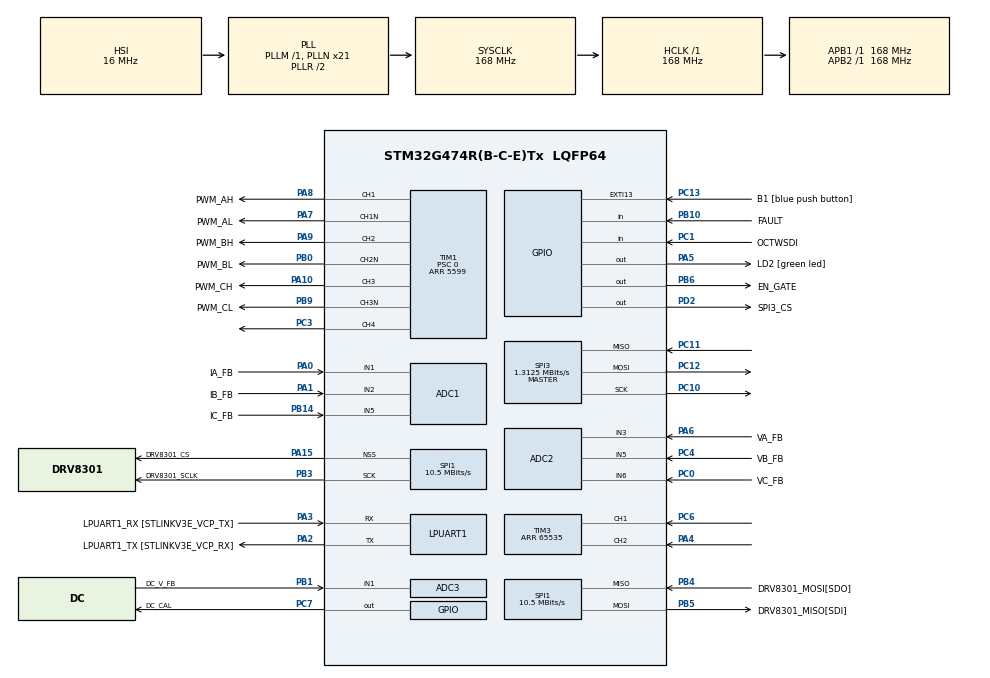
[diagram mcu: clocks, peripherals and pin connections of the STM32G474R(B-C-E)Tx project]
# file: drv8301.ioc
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ADC1.AWD1HighThreshold=4095
ADC1.AWD1ITMode=ENABLE
ADC1.Channel-0\#ChannelRegularConversion=ADC_CHANNEL_1
ADC1.Channel-2\#ChannelRegularConversion=ADC_CHANNEL_2
ADC1.Channel-3\#ChannelRegularConversion=ADC_CHANNEL_5
ADC1.ContinuousConvMode=DISABLE
ADC1.DMAAccessModeView=ENABLE
ADC1.DMAContinuousRequests=ENABLE
ADC1.EnableAnalogWatchDog1=true
ADC1.EnableInjectedConversion=ENABLE
ADC1.ExternalTrigInjecConv=ADC_EXTERNALTRIGINJEC_T1_TRGO2
ADC1.InjNumberOfConversion=3
ADC1.InjectedChannel-1\#ChannelInjectedConversion=ADC_CHANNEL_1
ADC1.InjectedChannel-4\#ChannelInjectedConversion=ADC_CHANNEL_2
ADC1.InjectedChannel-5\#ChannelInjectedConversion=ADC_CHANNEL_5
ADC1.InjectedConvMode=Discontinuous
ADC1.InjectedOffsetNumber-1\#ChannelInjectedConversion=ADC_OFFSET_NONE
ADC1.InjectedOffsetNumber-4\#ChannelInjectedConversion=ADC_OFFSET_NONE
ADC1.InjectedOffsetNumber-5\#ChannelInjectedConversion=ADC_OFFSET_NONE
ADC1.InjectedRank-1\#ChannelInjectedConversion=1
ADC1.InjectedRank-4\#ChannelInjectedConversion=2
ADC1.InjectedRank-5\#ChannelInjectedConversion=3
ADC1.InjectedSamplingTime-1\#ChannelInjectedConversion=ADC_SAMPLETIME_6CYCLES_5
ADC1.InjectedSamplingTime-4\#ChannelInjectedConversion=ADC_SAMPLETIME_6CYCLES_5
ADC1.InjectedSamplingTime-5\#ChannelInjectedConversion=ADC_SAMPLETIME_6CYCLES_5
ADC1.Mode=ADC_DUALMODE_REGSIMULT_INJECSIMULT
ADC1.NbrOfConversion=3
ADC1.NbrOfConversionFlag=1
ADC1.OffsetNumber-0\#ChannelRegularConversion=ADC_OFFSET_NONE
ADC1.OffsetNumber-2\#ChannelRegularConversion=ADC_OFFSET_NONE
ADC1.OffsetNumber-3\#ChannelRegularConversion=ADC_OFFSET_NONE
ADC1.Rank-0\#ChannelRegularConversion=1
ADC1.Rank-2\#ChannelRegularConversion=2
ADC1.Rank-3\#ChannelRegularConversion=3
ADC1.Rank2_Channel=ADC_CHANNEL_2
ADC1.Rank3_Channel=ADC_CHANNEL_5
ADC1.SamplingTime-0\#ChannelRegularConversion=ADC_SAMPLETIME_6CYCLES_5
ADC1.SamplingTime-2\#ChannelRegularConversion=ADC_SAMPLETIME_6CYCLES_5
ADC1.SamplingTime-3\#ChannelRegularConversion=ADC_SAMPLETIME_6CYCLES_5
ADC1.WatchdogMode=ADC_ANALOGWATCHDOG_ALL_REGINJEC
ADC1.injectedQueueMode=DISABLE
ADC1.master=1
ADC2.AWD1HighThreshold=4095
ADC2.AWD1ITMode=ENABLE
ADC2.Channel-1\#ChannelRegularConversion=ADC_CHANNEL_3
ADC2.Channel-2\#ChannelRegularConversion=ADC_CHANNEL_5
ADC2.Channel-3\#ChannelRegularConversion=ADC_CHANNEL_6
ADC2.DMAAccessModeView=ENABLE
ADC2.DMAContinuousRequests=ENABLE
ADC2.EnableAnalogWatchDog1=true
ADC2.EnableInjectedConversion=ENABLE
ADC2.InjNumberOfConversion=3
ADC2.InjectedChannel-4\#ChannelInjectedConversion=ADC_CHANNEL_3
ADC2.InjectedChannel-5\#ChannelInjectedConversion=ADC_CHANNEL_5
ADC2.InjectedChannel-6\#ChannelInjectedConversion=ADC_CHANNEL_6
ADC2.InjectedConvMode=Discontinuous
ADC2.InjectedOffsetNumber-4\#ChannelInjectedConversion=ADC_OFFSET_NONE
ADC2.InjectedOffsetNumber-5\#ChannelInjectedConversion=ADC_OFFSET_NONE
ADC2.InjectedOffsetNumber-6\#ChannelInjectedConversion=ADC_OFFSET_NONE
ADC2.InjectedRank-4\#ChannelInjectedConversion=1
ADC2.InjectedRank-5\#ChannelInjectedConversion=2
ADC2.InjectedRank-6\#ChannelInjectedConversion=3
ADC2.InjectedSamplingTime-4\#ChannelInjectedConversion=ADC_SAMPLETIME_6CYCLES_5
ADC2.InjectedSamplingTime-5\#ChannelInjectedConversion=ADC_SAMPLETIME_6CYCLES_5
ADC2.InjectedSamplingTime-6\#ChannelInjectedConversion=ADC_SAMPLETIME_6CYCLES_5
ADC2.Mode=ADC_DUALMODE_REGSIMULT_INJECSIMULT
ADC2.NbrOfConversion=3
ADC2.NbrOfConversionFlag=1
ADC2.OffsetNumber-1\#ChannelRegularConversion=ADC_OFFSET_NONE
ADC2.OffsetNumber-2\#ChannelRegularConversion=ADC_OFFSET_NONE
ADC2.OffsetNumber-3\#ChannelRegularConversion=ADC_OFFSET_NONE
ADC2.Rank-1\#ChannelRegularConversion=1
ADC2.Rank-2\#ChannelRegularConversion=2
ADC2.Rank-3\#ChannelRegularConversion=3
ADC2.Rank1_Channel=ADC_CHANNEL_3
ADC2.Rank2_Channel=ADC_CHANNEL_5
ADC2.Rank3_Channel=ADC_CHANNEL_6
ADC2.SamplingTime-1\#ChannelRegularConversion=ADC_SAMPLETIME_6CYCLES_5
ADC2.SamplingTime-2\#ChannelRegularConversion=ADC_SAMPLETIME_6CYCLES_5
ADC2.SamplingTime-3\#ChannelRegularConversion=ADC_SAMPLETIME_6CYCLES_5
ADC2.WatchdogMode=ADC_ANALOGWATCHDOG_ALL_REGINJEC
ADC2.injectedQueueMode=DISABLE
ADC3.Channel-1\#ChannelRegularConversion=ADC_CHANNEL_1
ADC3.ContinuousConvMode=ENABLE
ADC3.NbrOfConversionFlag=1
ADC3.OffsetNumber-1\#ChannelRegularConversion=ADC_OFFSET_NONE
ADC3.Rank-1\#ChannelRegularConversion=1
ADC3.SamplingTime-1\#ChannelRegularConversion=ADC_SAMPLETIME_24CYCLES_5
ADC3.master=1
Dma.ADC1.0.Direction=DMA_PERIPH_TO_MEMORY
Dma.ADC1.0.EventEnable=DISABLE
Dma.ADC1.0.Instance=DMA1_Channel1
Dma.ADC1.0.MemDataAlignment=DMA_MDATAALIGN_HALFWORD
Dma.ADC1.0.MemInc=DMA_MINC_ENABLE
Dma.ADC1.0.Mode=DMA_CIRCULAR
Dma.ADC1.0.PeriphDataAlignment=DMA_PDATAALIGN_HALFWORD
Dma.ADC1.0.PeriphInc=DMA_PINC_DISABLE
Dma.ADC1.0.Polarity=HAL_DMAMUX_REQ_GEN_RISING
Dma.ADC1.0.Priority=DMA_PRIORITY_LOW
Dma.ADC1.0.RequestNumber=1
Dma.ADC1.0.SignalID=NONE
Dma.ADC1.0.SyncEnable=DISABLE
Dma.ADC1.0.SyncPolarity=HAL_DMAMUX_SYNC_NO_EVENT
Dma.ADC1.0.SyncRequestNumber=1
Dma.ADC1.0.SyncSignalID=NONE
Dma.ADC2.1.Direction=DMA_PERIPH_TO_MEMORY
Dma.ADC2.1.EventEnable=DISABLE
Dma.ADC2.1.Instance=DMA1_Channel2
Dma.ADC2.1.MemDataAlignment=DMA_MDATAALIGN_HALFWORD
Dma.ADC2.1.MemInc=DMA_MINC_ENABLE
Dma.ADC2.1.Mode=DMA_CIRCULAR
Dma.ADC2.1.PeriphDataAlignment=DMA_PDATAALIGN_HALFWORD
Dma.ADC2.1.PeriphInc=DMA_PINC_DISABLE
Dma.ADC2.1.Polarity=HAL_DMAMUX_REQ_GEN_RISING
Dma.ADC2.1.Priority=DMA_PRIORITY_LOW
Dma.ADC2.1.RequestNumber=1
Dma.ADC2.1.SignalID=NONE
Dma.ADC2.1.SyncEnable=DISABLE
Dma.ADC2.1.SyncPolarity=HAL_DMAMUX_SYNC_NO_EVENT
Dma.ADC2.1.SyncRequestNumber=1
Dma.ADC2.1.SyncSignalID=NONE
Dma.Request0=ADC1
Dma.Request1=ADC2
Dma.Request2=TIM3_UP
Dma.Request3=SPI1_TX
Dma.Request4=SPI1_RX
Dma.Request5=SPI3_RX
Dma.Request6=SPI3_TX
Dma.SPI1_RX.4.Direction=DMA_PERIPH_TO_MEMORY
Dma.SPI1_RX.4.EventEnable=DISABLE
Dma.SPI1_RX.4.Instance=DMA1_Channel5
Dma.SPI1_RX.4.MemDataAlignment=DMA_MDATAALIGN_HALFWORD
Dma.SPI1_RX.4.MemInc=DMA_MINC_ENABLE
Dma.SPI1_RX.4.Mode=DMA_NORMAL
Dma.SPI1_RX.4.PeriphDataAlignment=DMA_PDATAALIGN_HALFWORD
Dma.SPI1_RX.4.PeriphInc=DMA_PINC_DISABLE
Dma.SPI1_RX.4.Polarity=HAL_DMAMUX_REQ_GEN_RISING
Dma.SPI1_RX.4.Priority=DMA_PRIORITY_LOW
Dma.SPI1_RX.4.RequestNumber=1
Dma.SPI1_RX.4.SignalID=NONE
Dma.SPI1_RX.4.SyncEnable=DISABLE
Dma.SPI1_RX.4.SyncPolarity=HAL_DMAMUX_SYNC_NO_EVENT
Dma.SPI1_RX.4.SyncRequestNumber=1
Dma.SPI1_RX.4.SyncSignalID=NONE
Dma.SPI1_TX.3.Direction=DMA_MEMORY_TO_PERIPH
Dma.SPI1_TX.3.EventEnable=DISABLE
Dma.SPI1_TX.3.Instance=DMA1_Channel4
Dma.SPI1_TX.3.MemDataAlignment=DMA_MDATAALIGN_HALFWORD
Dma.SPI1_TX.3.MemInc=DMA_MINC_ENABLE
Dma.SPI1_TX.3.Mode=DMA_NORMAL
Dma.SPI1_TX.3.PeriphDataAlignment=DMA_PDATAALIGN_HALFWORD
Dma.SPI1_TX.3.PeriphInc=DMA_PINC_DISABLE
Dma.SPI1_TX.3.Polarity=HAL_DMAMUX_REQ_GEN_RISING
Dma.SPI1_TX.3.Priority=DMA_PRIORITY_LOW
Dma.SPI1_TX.3.RequestNumber=1
Dma.SPI1_TX.3.SignalID=NONE
Dma.SPI1_TX.3.SyncEnable=DISABLE
Dma.SPI1_TX.3.SyncPolarity=HAL_DMAMUX_SYNC_NO_EVENT
Dma.SPI1_TX.3.SyncRequestNumber=1
Dma.SPI1_TX.3.SyncSignalID=NONE
Dma.SPI3_RX.5.Direction=DMA_PERIPH_TO_MEMORY
Dma.SPI3_RX.5.EventEnable=DISABLE
Dma.SPI3_RX.5.Instance=DMA1_Channel6
Dma.SPI3_RX.5.MemDataAlignment=DMA_MDATAALIGN_HALFWORD
Dma.SPI3_RX.5.MemInc=DMA_MINC_ENABLE
Dma.SPI3_RX.5.Mode=DMA_NORMAL
Dma.SPI3_RX.5.PeriphDataAlignment=DMA_PDATAALIGN_HALFWORD
Dma.SPI3_RX.5.PeriphInc=DMA_PINC_DISABLE
Dma.SPI3_RX.5.Polarity=HAL_DMAMUX_REQ_GEN_RISING
Dma.SPI3_RX.5.Priority=DMA_PRIORITY_VERY_HIGH
Dma.SPI3_RX.5.RequestNumber=1
Dma.SPI3_RX.5.SignalID=NONE
Dma.SPI3_RX.5.SyncEnable=DISABLE
Dma.SPI3_RX.5.SyncPolarity=HAL_DMAMUX_SYNC_NO_EVENT
Dma.SPI3_RX.5.SyncRequestNumber=1
Dma.SPI3_RX.5.SyncSignalID=NONE
Dma.SPI3_TX.6.Direction=DMA_MEMORY_TO_PERIPH
Dma.SPI3_TX.6.EventEnable=DISABLE
Dma.SPI3_TX.6.Instance=DMA1_Channel7
Dma.SPI3_TX.6.MemDataAlignment=DMA_MDATAALIGN_HALFWORD
Dma.SPI3_TX.6.MemInc=DMA_MINC_ENABLE
Dma.SPI3_TX.6.Mode=DMA_NORMAL
Dma.SPI3_TX.6.PeriphDataAlignment=DMA_PDATAALIGN_HALFWORD
Dma.SPI3_TX.6.PeriphInc=DMA_PINC_DISABLE
Dma.SPI3_TX.6.Polarity=HAL_DMAMUX_REQ_GEN_RISING
Dma.SPI3_TX.6.Priority=DMA_PRIORITY_VERY_HIGH
Dma.SPI3_TX.6.RequestNumber=1
Dma.SPI3_TX.6.SignalID=NONE
Dma.SPI3_TX.6.SyncEnable=DISABLE
Dma.SPI3_TX.6.SyncPolarity=HAL_DMAMUX_SYNC_NO_EVENT
Dma.SPI3_TX.6.SyncRequestNumber=1
Dma.SPI3_TX.6.SyncSignalID=NONE
Dma.TIM3_UP.2.Direction=DMA_PERIPH_TO_MEMORY
Dma.TIM3_UP.2.EventEnable=DISABLE
Dma.TIM3_UP.2.Instance=DMA1_Channel3
Dma.TIM3_UP.2.MemDataAlignment=DMA_MDATAALIGN_HALFWORD
Dma.TIM3_UP.2.MemInc=DMA_MINC_ENABLE
Dma.TIM3_UP.2.Mode=DMA_NORMAL
Dma.TIM3_UP.2.PeriphDataAlignment=DMA_PDATAALIGN_HALFWORD
Dma.TIM3_UP.2.PeriphInc=DMA_PINC_DISABLE
Dma.TIM3_UP.2.Polarity=HAL_DMAMUX_REQ_GEN_RISING
Dma.TIM3_UP.2.Priority=DMA_PRIORITY_HIGH
Dma.TIM3_UP.2.RequestNumber=1
Dma.TIM3_UP.2.SignalID=NONE
Dma.TIM3_UP.2.SyncEnable=DISABLE
Dma.TIM3_UP.2.SyncPolarity=HAL_DMAMUX_SYNC_NO_EVENT
Dma.TIM3_UP.2.SyncRequestNumber=1
Dma.TIM3_UP.2.SyncSignalID=NONE
Mcu.Family=STM32G4
Mcu.Name=STM32G474R(B-C-E)Tx
Mcu.Package=LQFP64
NVIC.ADC1_2_IRQn=true\:0\:0\:false\:false\:true\:true\:true\:true
NVIC.DMA1_Channel1_IRQn=true\:0\:0\:false\:false\:true\:false\:true\:true
NVIC.DMA1_Channel2_IRQn=true\:0\:0\:false\:false\:true\:false\:true\:true
NVIC.DMA1_Channel3_IRQn=true\:0\:0\:false\:false\:true\:false\:true\:true
NVIC.DMA1_Channel4_IRQn=true\:0\:0\:false\:false\:true\:false\:true\:true
NVIC.DMA1_Channel5_IRQn=true\:0\:0\:false\:false\:true\:false\:true\:true
NVIC.DMA1_Channel6_IRQn=true\:0\:0\:false\:false\:true\:false\:true\:true
NVIC.DMA1_Channel7_IRQn=true\:0\:0\:false\:false\:true\:false\:true\:true
NVIC.EXTI15_10_IRQn=true\:3\:0\:true\:false\:true\:true\:true\:true
NVIC.PriorityGroup=NVIC_PRIORITYGROUP_2
NVIC.SPI3_IRQn=true\:0\:0\:false\:false\:true\:true\:true\:true
NVIC.TIM3_IRQn=true\:0\:0\:true\:false\:true\:true\:true\:true
PA0.GPIO_Label=IA_FB
PA0.Mode=IN1-Single-Ended
PA0.Signal=ADC1_IN1
PA1.GPIO_Label=IB_FB
PA1.Mode=IN2-Single-Ended
PA1.Signal=ADC1_IN2
PA10.GPIO_Label=PWM_CH
PA10.Signal=S_TIM1_CH3
PA13.GPIO_Label=T_SWDIO
PA13.Mode=Serial_Wire
PA13.Signal=SYS_JTMS-SWDIO
PA14.GPIO_Label=T_SWCLK
PA14.Mode=Serial_Wire
PA14.Signal=SYS_JTCK-SWCLK
PA15.GPIO_Label=DRV8301_CS
PA15.Mode=NSS_Signal_Hard_Output
PA15.Signal=SPI1_NSS
PA2.GPIO_Label=LPUART1_TX [STLINKV3E_VCP_RX]
PA2.Mode=Asynchronous
PA2.Signal=LPUART1_TX
PA3.GPIO_Label=LPUART1_RX [STLINKV3E_VCP_TX]
PA3.Mode=Asynchronous
PA3.Signal=LPUART1_RX
PA4.Signal=S_TIM3_CH2
PA5.GPIO_Label=LD2 [green led]
PA5.Signal=GPIO_Output
PA6.GPIO_Label=VA_FB
PA6.Mode=IN3-Single-Ended
PA6.Signal=ADC2_IN3
PA7.GPIO_Label=PWM_AL
PA7.Mode=PWM Generation1 CH1 CH1N
PA7.Signal=TIM1_CH1N
PA8.GPIO_Label=PWM_AH
PA8.Signal=S_TIM1_CH1
PA9.GPIO_Label=PWM_BH
PA9.Signal=S_TIM1_CH2
PB0.GPIO_Label=PWM_BL
PB0.Mode=PWM Generation2 CH2 CH2N
PB0.Signal=TIM1_CH2N
PB1.GPIO_Label=DC_V_FB
PB1.Mode=IN1-Single-Ended
PB1.Signal=ADC3_IN1
PB10.GPIO_Label=FAULT
PB10.Signal=GPIO_Input
PB14.GPIO_Label=IC_FB
PB14.Mode=IN5-Single-Ended
PB14.Signal=ADC1_IN5
PB3.GPIO_Label=DRV8301_SCLK
PB3.Mode=Full_Duplex_Master
PB3.Signal=SPI1_SCK
PB4.GPIO_Label=DRV8301_MOSI[SDO]
PB4.Mode=Full_Duplex_Master
PB4.Signal=SPI1_MISO
PB5.GPIO_Label=DRV8301_MISO[SDI]
PB5.Mode=Full_Duplex_Master
PB5.Signal=SPI1_MOSI
PB6.GPIO_Label=EN_GATE
PB6.Signal=GPIO_Output
PB9.GPIO_Label=PWM_CL
PB9.Mode=PWM Generation3 CH3 CH3N
PB9.Signal=TIM1_CH3N
PC0.GPIO_Label=VC_FB
PC0.Mode=IN6-Single-Ended
PC0.Signal=ADC2_IN6
PC1.GPIO_Label=OCTWSDI
PC1.Signal=GPIO_Input
PC10.Mode=Full_Duplex_Master
PC10.Signal=SPI3_SCK
PC11.Mode=Full_Duplex_Master
PC11.Signal=SPI3_MISO
PC12.Mode=Full_Duplex_Master
PC12.Signal=SPI3_MOSI
PC13.GPIO_Label=B1 [blue push button]
PC13.Signal=GPXTI13
PC3.Signal=S_TIM1_CH4
PC4.GPIO_Label=VB_FB
PC4.Mode=IN5-Single-Ended
PC4.Signal=ADC2_IN5
PC6.Signal=S_TIM3_CH1
PC7.GPIO_Label=DC_CAL
PC7.Signal=GPIO_Output
PD2.GPIO_Label=SPI3_CS
PD2.Signal=GPIO_Output
PF0-OSC_IN.Mode=HSE-External-Oscillator
PF0-OSC_IN.Signal=RCC_OSC_IN
PF1-OSC_OUT.Mode=HSE-External-Oscillator
PF1-OSC_OUT.Signal=RCC_OSC_OUT
ProjectManager.HeapSize=0x200
ProjectManager.StackSize=0x400
ProjectManager.TargetToolchain=MDK-ARM V5.32
RCC.ADC12Freq_Value=168000000
RCC.ADC345Freq_Value=168000000
RCC.AHBFreq_Value=168000000
RCC.APB1Freq_Value=168000000
RCC.APB1TimFreq_Value=168000000
RCC.APB2Freq_Value=168000000
RCC.APB2TimFreq_Value=168000000
RCC.CortexFreq_Value=168000000
RCC.EXTERNAL_CLOCK_VALUE=12288000
RCC.HCLKFreq_Value=168000000
RCC.HSE_VALUE=24000000
RCC.HSI48_VALUE=48000000
RCC.HSI_VALUE=16000000
RCC.LSE_VALUE=32768
RCC.PLLN=21
RCC.RTCClockSelection=RCC_RTCCLKSOURCE_LSE
RCC.SYSCLKFreq_VALUE=168000000
RCC.SYSCLKSource=RCC_SYSCLKSOURCE_PLLCLK
RCC.USBFreq_Value=168000000
RCC.VCOOutputFreq_Value=336000000
SH.S_TIM1_CH1.0=TIM1_CH1,PWM Generation1 CH1 CH1N
SH.S_TIM1_CH2.0=TIM1_CH2,PWM Generation2 CH2 CH2N
SH.S_TIM1_CH3.0=TIM1_CH3,PWM Generation3 CH3 CH3N
SH.S_TIM1_CH4.0=TIM1_CH4,PWM Generation4 CH4
SH.S_TIM3_CH1.0=TIM3_CH1,Encoder_Interface
SH.S_TIM3_CH2.0=TIM3_CH2,Encoder_Interface
SPI1.BaudRatePrescaler=SPI_BAUDRATEPRESCALER_16
SPI1.CalculateBaudRate=10.5 MBits/s
SPI1.DataSize=SPI_DATASIZE_16BIT
SPI1.Direction=SPI_DIRECTION_2LINES
SPI1.Mode=SPI_MODE_MASTER
SPI1.VirtualNSS=VM_NSSHARD
SPI1.VirtualType=VM_MASTER
SPI3.BaudRatePrescaler=SPI_BAUDRATEPRESCALER_128
SPI3.CLKPhase=SPI_PHASE_2EDGE
SPI3.CalculateBaudRate=1.3125 MBits/s
SPI3.DataSize=SPI_DATASIZE_16BIT
SPI3.Direction=SPI_DIRECTION_2LINES
SPI3.Mode=SPI_MODE_MASTER
SPI3.VirtualType=VM_MASTER
TIM1.AsymmetricalDeadTime=DISABLE
TIM1.AutoReloadPreload=TIM_AUTORELOAD_PRELOAD_ENABLE
TIM1.AutomaticOutput=TIM_AUTOMATICOUTPUT_ENABLE
TIM1.BreakState=TIM_BREAK_DISABLE
TIM1.Channel-PWM\ Generation1\ CH1\ CH1N=TIM_CHANNEL_1
TIM1.Channel-PWM\ Generation2\ CH2\ CH2N=TIM_CHANNEL_2
TIM1.Channel-PWM\ Generation3\ CH3\ CH3N=TIM_CHANNEL_3
TIM1.Channel-PWM\ Generation4\ CH4=TIM_CHANNEL_4
TIM1.CounterMode=TIM_COUNTERMODE_CENTERALIGNED2
TIM1.DeadTime=192
TIM1.DeadTimePreload=ENABLE
TIM1.OCFastMode_PWM-PWM\ Generation1\ CH1\ CH1N=TIM_OCFAST_DISABLE
TIM1.OCMode_PWM-PWM\ Generation1\ CH1\ CH1N=TIM_OCMODE_PWM2
TIM1.OCMode_PWM-PWM\ Generation2\ CH2\ CH2N=TIM_OCMODE_PWM2
TIM1.OCMode_PWM-PWM\ Generation3\ CH3\ CH3N=TIM_OCMODE_PWM2
TIM1.OCMode_PWM-PWM\ Generation4\ CH4=TIM_OCMODE_PWM2
TIM1.OffStateRunMode=TIM_OSSR_DISABLE
TIM1.PeriodNoDither=5599
TIM1.Prescaler=0
TIM1.PulseNoDither_1=5599
TIM1.PulseNoDither_2=5599
TIM1.PulseNoDither_3=5599
TIM1.PulseNoDither_4=10
TIM1.TIM_MasterOutputTrigger2=TIM_TRGO2_OC4REF_RISINGFALLING
TIM3.AutoReloadPreload=TIM_AUTORELOAD_PRELOAD_DISABLE
TIM3.EncoderMode=TIM_ENCODERMODE_TI12
TIM3.IC1Filter=1
TIM3.IC1Polarity=TIM_ICPOLARITY_FALLING
TIM3.IC2Filter=1
TIM3.IC2Polarity=TIM_ICPOLARITY_FALLING
TIM3.PeriodNoDither=65535
VP_SYS_VS_DBSignals.Mode=DisableDeadBatterySignals
VP_TIM1_VS_ClockSourceINT.Mode=Internal
board=NUCLEO-G474RE

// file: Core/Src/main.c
/* USER CODE BEGIN Header */
/**
  ******************************************************************************
  * @file           : main.c
  * @brief          : Main program body
  ******************************************************************************
  * @attention
  *
  * Copyright (c) 2024 STMicroelectronics.
  * All rights reserved.
  *
  * This software is licensed under terms that can be found in the LICENSE file
  * in the root directory of this software component.
  * If no LICENSE file comes with this software, it is provided AS-IS.
  *
  ******************************************************************************
  */
/* USER CODE END Header */
#include "main.h"
#include "adc.h"
#include "dma.h"
#include "usart.h"
#include "spi.h"
#include "tim.h"
#include "gpio.h"

/* USER CODE BEGIN Includes */
#include "stdbool.h"
#include "controller.h"
#include "align.h"
#include "stdlib.h"
#include "encoder.h"
/* USER CODE END Includes */

void SystemClock_Config(void);

int main(void)
{

  /* MCU Configuration--------------------------------------------------------*/

  /* Reset of all peripherals, Initializes the Flash interface and the Systick. */
  HAL_Init();

  /* Configure the system clock */
  SystemClock_Config();

  /* Initialize all configured peripherals */
  MX_GPIO_Init();
  MX_DMA_Init();
  MX_ADC1_Init();
  MX_ADC2_Init();
  MX_ADC3_Init();
  MX_LPUART1_UART_Init();
  MX_SPI1_Init();
  MX_TIM1_Init();
  MX_TIM3_Init();
  MX_SPI3_Init();

  /* Infinite loop */
  /* USER CODE BEGIN WHILE */
  while (1)
  {
	main_entery();
    /* USER CODE END WHILE */

  }
}

void SystemClock_Config(void)
{
  RCC_OscInitTypeDef RCC_OscInitStruct = {0};
  RCC_ClkInitTypeDef RCC_ClkInitStruct = {0};

  /** Configure the main internal regulator output voltage
  */
  HAL_PWREx_ControlVoltageScaling(PWR_REGULATOR_VOLTAGE_SCALE1_BOOST);

  /** Initializes the RCC Oscillators according to the specified parameters
  * in the RCC_OscInitTypeDef structure.
  */
  RCC_OscInitStruct.OscillatorType = RCC_OSCILLATORTYPE_HSI;
  RCC_OscInitStruct.HSIState = RCC_HSI_ON;
  RCC_OscInitStruct.HSICalibrationValue = RCC_HSICALIBRATION_DEFAULT;
  RCC_OscInitStruct.PLL.PLLState = RCC_PLL_ON;
  RCC_OscInitStruct.PLL.PLLSource = RCC_PLLSOURCE_HSI;
  RCC_OscInitStruct.PLL.PLLM = RCC_PLLM_DIV1;
  RCC_OscInitStruct.PLL.PLLN = 21;
  RCC_OscInitStruct.PLL.PLLP = RCC_PLLP_DIV2;
  RCC_OscInitStruct.PLL.PLLQ = RCC_PLLQ_DIV2;
  RCC_OscInitStruct.PLL.PLLR = RCC_PLLR_DIV2;
  if (HAL_RCC_OscConfig(&RCC_OscInitStruct) != HAL_OK)
  {
    Error_Handler();
  }

  /** Initializes the CPU, AHB and APB buses clocks
  */
  RCC_ClkInitStruct.ClockType = RCC_CLOCKTYPE_HCLK|RCC_CLOCKTYPE_SYSCLK
                              |RCC_CLOCKTYPE_PCLK1|RCC_CLOCKTYPE_PCLK2;
  RCC_ClkInitStruct.SYSCLKSource = RCC_SYSCLKSOURCE_PLLCLK;
  RCC_ClkInitStruct.AHBCLKDivider = RCC_SYSCLK_DIV1;
  RCC_ClkInitStruct.APB1CLKDivider = RCC_HCLK_DIV1;
  RCC_ClkInitStruct.APB2CLKDivider = RCC_HCLK_DIV1;

  if (HAL_RCC_ClockConfig(&RCC_ClkInitStruct, FLASH_LATENCY_4) != HAL_OK)
  {
    Error_Handler();
  }
}

void Error_Handler(void)
{
  __disable_irq();
  while (1)
  {
  }
}
